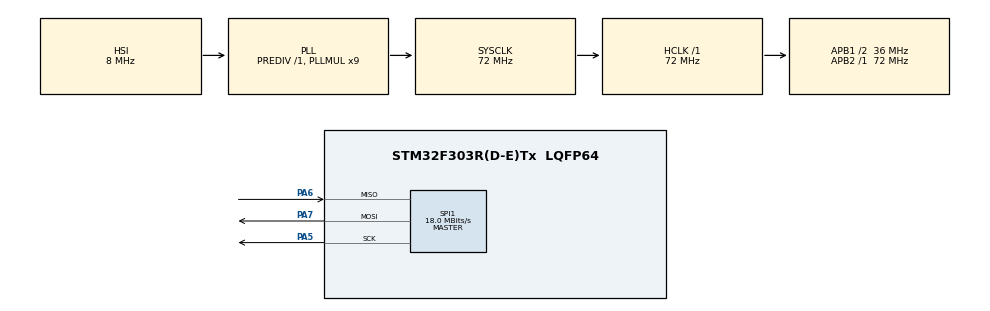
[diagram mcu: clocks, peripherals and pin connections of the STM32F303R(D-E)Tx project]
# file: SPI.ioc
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Dma.Request0=SPI1_TX
Dma.SPI1_TX.0.Direction=DMA_MEMORY_TO_PERIPH
Dma.SPI1_TX.0.Instance=DMA1_Channel3
Dma.SPI1_TX.0.MemDataAlignment=DMA_MDATAALIGN_BYTE
Dma.SPI1_TX.0.MemInc=DMA_MINC_ENABLE
Dma.SPI1_TX.0.Mode=DMA_NORMAL
Dma.SPI1_TX.0.PeriphDataAlignment=DMA_PDATAALIGN_BYTE
Dma.SPI1_TX.0.PeriphInc=DMA_PINC_DISABLE
Dma.SPI1_TX.0.Priority=DMA_PRIORITY_LOW
Mcu.Family=STM32F3
Mcu.Name=STM32F303R(D-E)Tx
Mcu.Package=LQFP64
NVIC.DMA1_Channel3_IRQn=true\:0\:0\:false\:false\:true\:false\:true\:true
NVIC.PriorityGroup=NVIC_PRIORITYGROUP_0
NVIC.SPI1_IRQn=true\:0\:0\:false\:false\:true\:true\:true\:true
PA5.Mode=Full_Duplex_Master
PA5.Signal=SPI1_SCK
PA6.Mode=Full_Duplex_Master
PA6.Signal=SPI1_MISO
PA7.Mode=Full_Duplex_Master
PA7.Signal=SPI1_MOSI
ProjectManager.HeapSize=0x200
ProjectManager.StackSize=0x400
ProjectManager.TargetToolchain=STM32CubeIDE
RCC.AHBFreq_Value=72000000
RCC.APB1CLKDivider=RCC_HCLK_DIV2
RCC.APB1Freq_Value=36000000
RCC.APB1TimFreq_Value=72000000
RCC.APB2Freq_Value=72000000
RCC.APB2TimFreq_Value=72000000
RCC.CortexFreq_Value=72000000
RCC.HCLKFreq_Value=72000000
RCC.HSE_VALUE=8000000
RCC.HSI_VALUE=8000000
RCC.PLLM=8
RCC.PLLMUL=RCC_PLL_MUL9
RCC.PLLN=336
RCC.PLLP=RCC_PLLP_DIV4
RCC.PLLQ=7
RCC.RCC_PLLsource_Clock_Source_FROM_HSE=RCC_HSE_PREDIV_DIV2
RCC.SYSCLKFreq_VALUE=72000000
RCC.SYSCLKSourceVirtual=RCC_SYSCLKSOURCE_PLLCLK
RCC.USBFreq_Value=72000000
SPI1.BaudRatePrescaler=SPI_BAUDRATEPRESCALER_4
SPI1.CalculateBaudRate=18.0 MBits/s
SPI1.Direction=SPI_DIRECTION_2LINES
SPI1.Mode=SPI_MODE_MASTER
SPI1.VirtualType=VM_MASTER
board=NUCLEO-F303RE

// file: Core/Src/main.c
/* USER CODE BEGIN Header */
/**
  ******************************************************************************
  * @file           : main.c
  * @brief          : Main program body
  ******************************************************************************
  * @attention
  *
  * Copyright (c) 2025 STMicroelectronics.
  * All rights reserved.
  *
  * This software is licensed under terms that can be found in the LICENSE file
  * in the root directory of this software component.
  * If no LICENSE file comes with this software, it is provided AS-IS.
  *
  ******************************************************************************
  */
/* USER CODE END Header */
#include "main.h"

SPI_HandleTypeDef hspi1;
DMA_HandleTypeDef hdma_spi1_tx;

/* USER CODE BEGIN PV */
uint8_t TX_Buffer[] = {10} ; // DATA to send
/* USER CODE END PV */

void SystemClock_Config(void);
static void MX_GPIO_Init(void);
static void MX_DMA_Init(void);
static void MX_SPI1_Init(void);

int main(void)
{

  /* MCU Configuration--------------------------------------------------------*/

  /* Reset of all peripherals, Initializes the Flash interface and the Systick. */
  HAL_Init();

  /* Configure the system clock */
  SystemClock_Config();

  /* Initialize all configured peripherals */
  MX_GPIO_Init();
  MX_DMA_Init();
  MX_SPI1_Init();
  /* USER CODE BEGIN 2 */

  /* Infinite loop */
  /* USER CODE BEGIN WHILE */
  while (1)
  {
    /* USER CODE END WHILE */
	  HAL_SPI_Transmit(&hspi1, TX_Buffer, 1, 1000); //Sending in Blocking mode
	  HAL_Delay(100);
	  /* USER CODE END 2 */
  }
}

void SystemClock_Config(void)
{
  RCC_OscInitTypeDef RCC_OscInitStruct = {0};
  RCC_ClkInitTypeDef RCC_ClkInitStruct = {0};

  /** Initializes the RCC Oscillators according to the specified parameters
  * in the RCC_OscInitTypeDef structure.
  */
  RCC_OscInitStruct.OscillatorType = RCC_OSCILLATORTYPE_HSI;
  RCC_OscInitStruct.HSIState = RCC_HSI_ON;
  RCC_OscInitStruct.HSICalibrationValue = RCC_HSICALIBRATION_DEFAULT;
  RCC_OscInitStruct.PLL.PLLState = RCC_PLL_ON;
  RCC_OscInitStruct.PLL.PLLSource = RCC_PLLSOURCE_HSI;
  RCC_OscInitStruct.PLL.PLLMUL = RCC_PLL_MUL9;
  RCC_OscInitStruct.PLL.PREDIV = RCC_PREDIV_DIV1;
  if (HAL_RCC_OscConfig(&RCC_OscInitStruct) != HAL_OK)
  {
    Error_Handler();
  }

  /** Initializes the CPU, AHB and APB buses clocks
  */
  RCC_ClkInitStruct.ClockType = RCC_CLOCKTYPE_HCLK|RCC_CLOCKTYPE_SYSCLK
                              |RCC_CLOCKTYPE_PCLK1|RCC_CLOCKTYPE_PCLK2;
  RCC_ClkInitStruct.SYSCLKSource = RCC_SYSCLKSOURCE_PLLCLK;
  RCC_ClkInitStruct.AHBCLKDivider = RCC_SYSCLK_DIV1;
  RCC_ClkInitStruct.APB1CLKDivider = RCC_HCLK_DIV2;
  RCC_ClkInitStruct.APB2CLKDivider = RCC_HCLK_DIV1;

  if (HAL_RCC_ClockConfig(&RCC_ClkInitStruct, FLASH_LATENCY_2) != HAL_OK)
  {
    Error_Handler();
  }
}

static void MX_SPI1_Init(void)
{

  /* SPI1 parameter configuration*/
  hspi1.Instance = SPI1;
  hspi1.Init.Mode = SPI_MODE_MASTER;
  hspi1.Init.Direction = SPI_DIRECTION_2LINES;
  hspi1.Init.DataSize = SPI_DATASIZE_4BIT;
  hspi1.Init.CLKPolarity = SPI_POLARITY_LOW;
  hspi1.Init.CLKPhase = SPI_PHASE_1EDGE;
  hspi1.Init.NSS = SPI_NSS_SOFT;
  hspi1.Init.BaudRatePrescaler = SPI_BAUDRATEPRESCALER_4;
  hspi1.Init.FirstBit = SPI_FIRSTBIT_MSB;
  hspi1.Init.TIMode = SPI_TIMODE_DISABLE;
  hspi1.Init.CRCCalculation = SPI_CRCCALCULATION_DISABLE;
  hspi1.Init.CRCPolynomial = 7;
  hspi1.Init.CRCLength = SPI_CRC_LENGTH_DATASIZE;
  hspi1.Init.NSSPMode = SPI_NSS_PULSE_ENABLE;
  if (HAL_SPI_Init(&hspi1) != HAL_OK)
  {
    Error_Handler();
  }

}

static void MX_DMA_Init(void)
{

  /* DMA controller clock enable */
  __HAL_RCC_DMA1_CLK_ENABLE();

  /* DMA interrupt init */
  /* DMA1_Channel3_IRQn interrupt configuration */
  HAL_NVIC_SetPriority(DMA1_Channel3_IRQn, 0, 0);
  HAL_NVIC_EnableIRQ(DMA1_Channel3_IRQn);

}

static void MX_GPIO_Init(void)
{

  /* GPIO Ports Clock Enable */
  __HAL_RCC_GPIOA_CLK_ENABLE();

}

void Error_Handler(void)
{
  __disable_irq();
  while (1)
  {
  }
}
